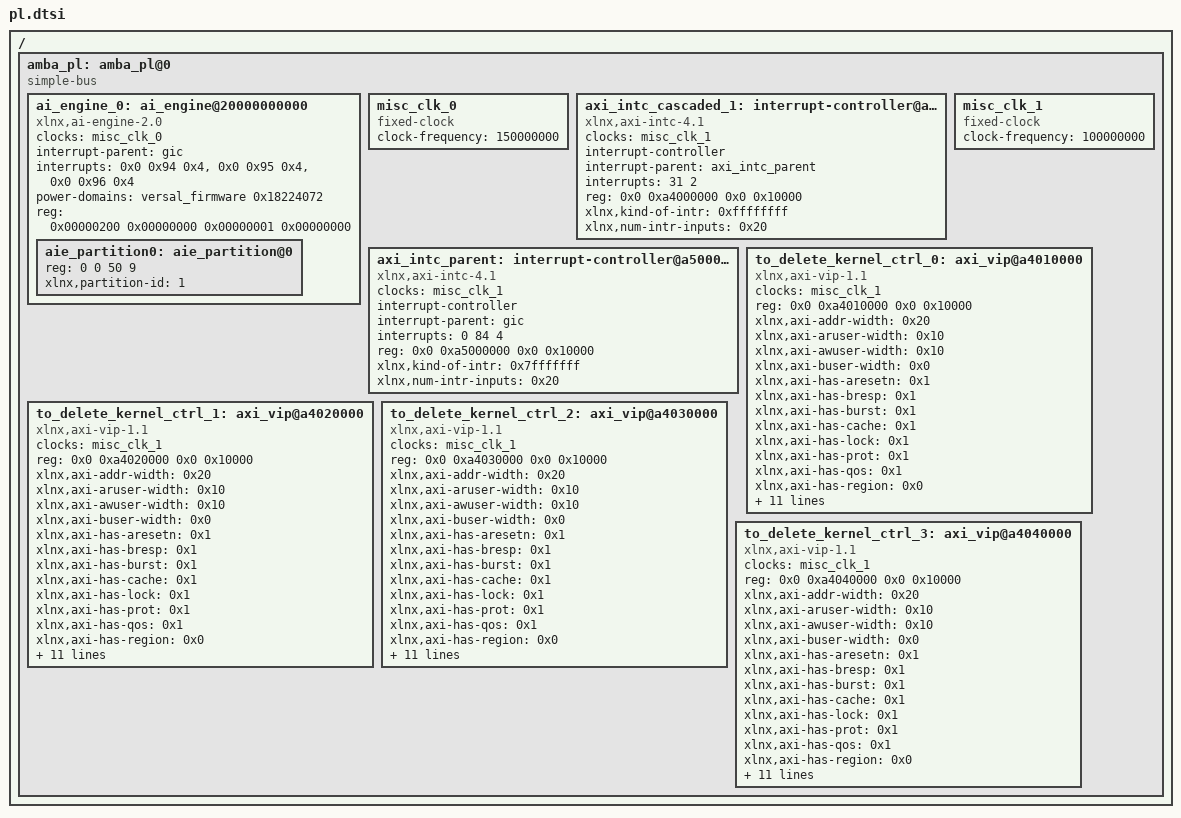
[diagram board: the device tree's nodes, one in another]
/*
 * CAUTION: This file is automatically generated by Xilinx.
 * Version:  
 * Today is: Fri Jun 11 15:16:47 2021
 */


/ {
	amba_pl: amba_pl@0 {
		#address-cells = <2>;
		#size-cells = <2>;
		compatible = "simple-bus";
		ranges ;
		ai_engine_0: ai_engine@20000000000 {
			#address-cells = <2>;
			#size-cells = <2>;
			clock-names = "aclk0";
			clocks = <&misc_clk_0>;
			compatible = "xlnx,ai-engine-2.0", "xlnx,ai-engine-v1.0";
			interrupt-names = "interrupt1", "interrupt2", "interrupt3";
			interrupt-parent = <&gic>;
			interrupts = <0x0 0x94 0x4>, <0x0 0x95 0x4>, <0x0 0x96 0x4>;
			power-domains = <&versal_firmware 0x18224072>;
			reg = <0x00000200 0x00000000 0x00000001 0x00000000>;
			aie_partition0: aie_partition@0 {
				reg = <0 0 50 9>;
				xlnx,partition-id = <1>;
			};
		};
		misc_clk_0: misc_clk_0 {
			#clock-cells = <0>;
			clock-frequency = <150000000>;
			compatible = "fixed-clock";
		};
		axi_intc_cascaded_1: interrupt-controller@a4000000 {
			#interrupt-cells = <2>;
			clock-names = "s_axi_aclk";
			clocks = <&misc_clk_1>;
			compatible = "xlnx,axi-intc-4.1", "xlnx,xps-intc-1.00.a";
			interrupt-controller ;
			interrupt-names = "irq";
			interrupt-parent = <&axi_intc_parent>;
			interrupts = <31 2>;
			reg = <0x0 0xa4000000 0x0 0x10000>;
			xlnx,kind-of-intr = <0xffffffff>;
			xlnx,num-intr-inputs = <0x20>;
		};
		misc_clk_1: misc_clk_1 {
			#clock-cells = <0>;
			clock-frequency = <100000000>;
			compatible = "fixed-clock";
		};
		axi_intc_parent: interrupt-controller@a5000000 {
			#interrupt-cells = <2>;
			clock-names = "s_axi_aclk";
			clocks = <&misc_clk_1>;
			compatible = "xlnx,axi-intc-4.1", "xlnx,xps-intc-1.00.a";
			interrupt-controller ;
			interrupt-names = "irq";
			interrupt-parent = <&gic>;
			interrupts = <0 84 4>;
			reg = <0x0 0xa5000000 0x0 0x10000>;
			xlnx,kind-of-intr = <0x7fffffff>;
			xlnx,num-intr-inputs = <0x20>;
		};
		to_delete_kernel_ctrl_0: axi_vip@a4010000 {
			clock-names = "aclk";
			clocks = <&misc_clk_1>;
			compatible = "xlnx,axi-vip-1.1";
			reg = <0x0 0xa4010000 0x0 0x10000>;
			xlnx,axi-addr-width = <0x20>;
			xlnx,axi-aruser-width = <0x10>;
			xlnx,axi-awuser-width = <0x10>;
			xlnx,axi-buser-width = <0x0>;
			xlnx,axi-has-aresetn = <0x1>;
			xlnx,axi-has-bresp = <0x1>;
			xlnx,axi-has-burst = <0x1>;
			xlnx,axi-has-cache = <0x1>;
			xlnx,axi-has-lock = <0x1>;
			xlnx,axi-has-prot = <0x1>;
			xlnx,axi-has-qos = <0x1>;
			xlnx,axi-has-region = <0x0>;
			xlnx,axi-has-rresp = <0x1>;
			xlnx,axi-has-wstrb = <0x1>;
			xlnx,axi-interface-mode = <0x2>;
			xlnx,axi-protocol = <0x0>;
			xlnx,axi-rdata-width = <0x20>;
			xlnx,axi-rid-width = <0x0>;
			xlnx,axi-ruser-width = <0x0>;
			xlnx,axi-supports-narrow = <0x0>;
			xlnx,axi-wdata-width = <0x20>;
			xlnx,axi-wid-width = <0x0>;
			xlnx,axi-wuser-width = <0x0>;
		};
		to_delete_kernel_ctrl_1: axi_vip@a4020000 {
			clock-names = "aclk";
			clocks = <&misc_clk_1>;
			compatible = "xlnx,axi-vip-1.1";
			reg = <0x0 0xa4020000 0x0 0x10000>;
			xlnx,axi-addr-width = <0x20>;
			xlnx,axi-aruser-width = <0x10>;
			xlnx,axi-awuser-width = <0x10>;
			xlnx,axi-buser-width = <0x0>;
			xlnx,axi-has-aresetn = <0x1>;
			xlnx,axi-has-bresp = <0x1>;
			xlnx,axi-has-burst = <0x1>;
			xlnx,axi-has-cache = <0x1>;
			xlnx,axi-has-lock = <0x1>;
			xlnx,axi-has-prot = <0x1>;
			xlnx,axi-has-qos = <0x1>;
			xlnx,axi-has-region = <0x0>;
			xlnx,axi-has-rresp = <0x1>;
			xlnx,axi-has-wstrb = <0x1>;
			xlnx,axi-interface-mode = <0x2>;
			xlnx,axi-protocol = <0x0>;
			xlnx,axi-rdata-width = <0x20>;
			xlnx,axi-rid-width = <0x0>;
			xlnx,axi-ruser-width = <0x0>;
			xlnx,axi-supports-narrow = <0x0>;
			xlnx,axi-wdata-width = <0x20>;
			xlnx,axi-wid-width = <0x0>;
			xlnx,axi-wuser-width = <0x0>;
		};
		to_delete_kernel_ctrl_2: axi_vip@a4030000 {
			clock-names = "aclk";
			clocks = <&misc_clk_1>;
			compatible = "xlnx,axi-vip-1.1";
			reg = <0x0 0xa4030000 0x0 0x10000>;
			xlnx,axi-addr-width = <0x20>;
			xlnx,axi-aruser-width = <0x10>;
			xlnx,axi-awuser-width = <0x10>;
			xlnx,axi-buser-width = <0x0>;
			xlnx,axi-has-aresetn = <0x1>;
			xlnx,axi-has-bresp = <0x1>;
			xlnx,axi-has-burst = <0x1>;
			xlnx,axi-has-cache = <0x1>;
			xlnx,axi-has-lock = <0x1>;
			xlnx,axi-has-prot = <0x1>;
			xlnx,axi-has-qos = <0x1>;
			xlnx,axi-has-region = <0x0>;
			xlnx,axi-has-rresp = <0x1>;
			xlnx,axi-has-wstrb = <0x1>;
			xlnx,axi-interface-mode = <0x2>;
			xlnx,axi-protocol = <0x0>;
			xlnx,axi-rdata-width = <0x20>;
			xlnx,axi-rid-width = <0x0>;
			xlnx,axi-ruser-width = <0x0>;
			xlnx,axi-supports-narrow = <0x0>;
			xlnx,axi-wdata-width = <0x20>;
			xlnx,axi-wid-width = <0x0>;
			xlnx,axi-wuser-width = <0x0>;
		};
		to_delete_kernel_ctrl_3: axi_vip@a4040000 {
			clock-names = "aclk";
			clocks = <&misc_clk_1>;
			compatible = "xlnx,axi-vip-1.1";
			reg = <0x0 0xa4040000 0x0 0x10000>;
			xlnx,axi-addr-width = <0x20>;
			xlnx,axi-aruser-width = <0x10>;
			xlnx,axi-awuser-width = <0x10>;
			xlnx,axi-buser-width = <0x0>;
			xlnx,axi-has-aresetn = <0x1>;
			xlnx,axi-has-bresp = <0x1>;
			xlnx,axi-has-burst = <0x1>;
			xlnx,axi-has-cache = <0x1>;
			xlnx,axi-has-lock = <0x1>;
			xlnx,axi-has-prot = <0x1>;
			xlnx,axi-has-qos = <0x1>;
			xlnx,axi-has-region = <0x0>;
			xlnx,axi-has-rresp = <0x1>;
			xlnx,axi-has-wstrb = <0x1>;
			xlnx,axi-interface-mode = <0x2>;
			xlnx,axi-protocol = <0x0>;
			xlnx,axi-rdata-width = <0x20>;
			xlnx,axi-rid-width = <0x0>;
			xlnx,axi-ruser-width = <0x0>;
			xlnx,axi-supports-narrow = <0x0>;
			xlnx,axi-wdata-width = <0x20>;
			xlnx,axi-wid-width = <0x0>;
			xlnx,axi-wuser-width = <0x0>;
		};
	};
};
